# WBZ451 register map
Vendor: Microchip
Registers are 32-bit, read-write, reset 0x0 unless marked. A register's access mark holds for its fields unless they carry their own. Addresses are absolute, and some are shared; only a register's first bit layout is shown; [hi:lo] are bit positions; {n}, {i} and the like mark numbered series.

## DSCON
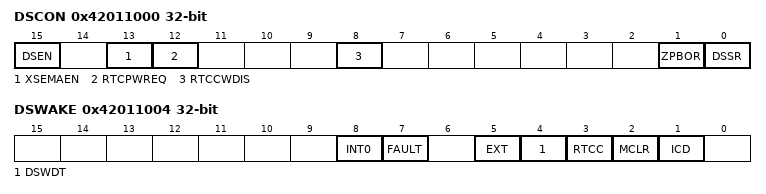
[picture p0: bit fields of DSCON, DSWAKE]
0x42011000 DSCON
  [15] DSEN, [13] XSEMAEN, [12] RTCPWREQ, [8] RTCCWDIS, [1] ZPBOR, [0] DSSR
0x42011004 DSWAKE
  [8] INT0, [7] FAULT, [5] EXT, [4] DSWDT, [3] RTCC, [2] MCLR, [1] ICD
0x42011008 DSSEMA1
  [31:0] DSSEMA
0x42011010 DSXSEMA1 reset not defined
  [31:0] DSXSEMA

## WDT
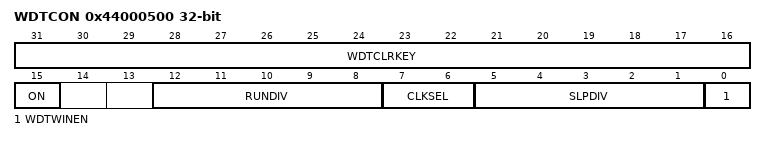
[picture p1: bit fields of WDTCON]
0x44000500 WDTCON reset not defined
  [31:16] WDTCLRKEY
  [15] ON — Watchdog Timer Enable bit
    1=WDTEN (The WDT module is enabled); 0=WDTOFF (The WDT module is disabled)
  [12:8] RUNDIV
  [7:6] CLKSEL
  [5:1] SLPDIV
  [0] WDTWINEN — Watchdog Timer Window Enable bit
    1=WDTWINEN (Enable windowed Watchdog Timer); 0=WDTWINDIS (Disable windowed Watchdog Timer)
0x44000504 WDTCONCLR
0x44000508 WDTCONSET
0x4400050C WDTCONINV

## NVM
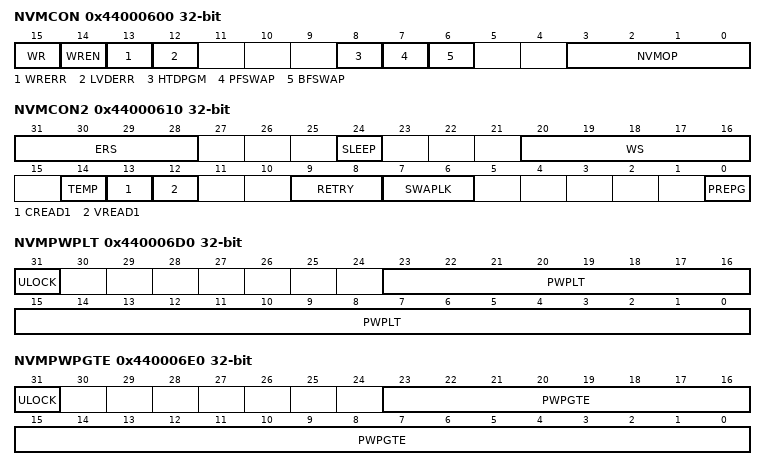
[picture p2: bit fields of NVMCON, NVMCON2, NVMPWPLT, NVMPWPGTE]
0x44000600 NVMCON
  [15] WR, [14] WREN, [13] WRERR, [12] LVDERR, [8] HTDPGM, [7] PFSWAP, [6] BFSWAP, [3:0] NVMOP
0x44000604 NVMCONCLR
0x44000608 NVMCONSET
0x4400060C NVMCONINV
0x44000610 NVMCON2
  [31:28] ERS, [24] SLEEP, [20:16] WS, [14] TEMP, [13] CREAD1, [12] VREAD1, [9:8] RETRY, [7:6] SWAPLK, [0] PREPG
0x44000614 NVMCON2CLR
0x44000618 NVMCON2SET
0x4400061C NVMCON2INV
0x44000620 NVMKEY
0x44000630 NVMADDR
{0x44000640+0x10*i} NVMDATA{i} (i=0..7)
0x440006C0 NVMSRCADDR
0x440006D0 NVMPWPLT
  [31] ULOCK, [23:0] PWPLT
0x440006D4 NVMPWPLTCLR
0x440006D8 NVMPWPLTSET
0x440006DC NVMPWPLTINV
0x440006E0 NVMPWPGTE
  [31] ULOCK, [23:0] PWPGTE
0x440006E4 NVMPWPGTECLR
0x440006E8 NVMPWPGTESET
0x440006EC NVMPWPGTEINV
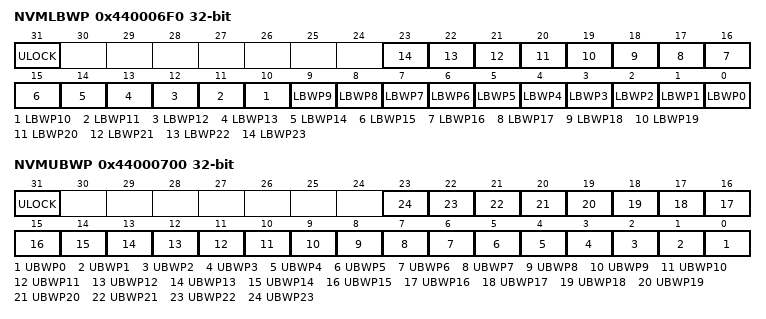
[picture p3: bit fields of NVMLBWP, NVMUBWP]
0x440006F0 NVMLBWP
  [31] ULOCK, [n] LBWP{n} (n=0..23)
0x440006F4 NVMLBWPCLR
0x440006F8 NVMLBWPSET
0x440006FC NVMLBWPINV
0x44000700 NVMUBWP
  [31] ULOCK, [n] UBWP{n} (n=0..23)
0x44000704 NVMUBWPCLR
0x44000708 NVMUBWPSET
0x4400070C NVMUBWPINV

## PFW
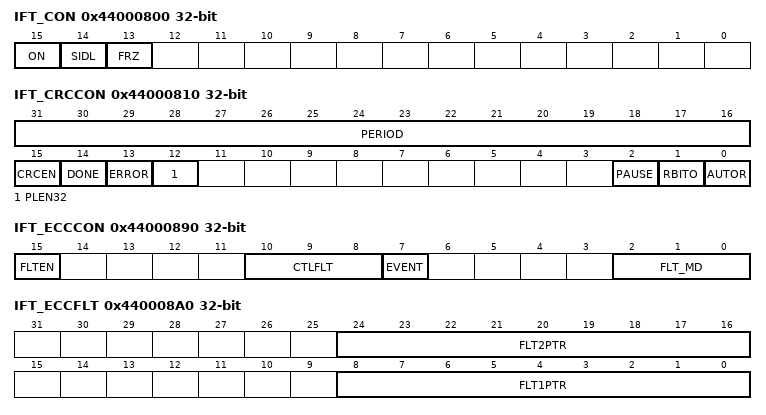
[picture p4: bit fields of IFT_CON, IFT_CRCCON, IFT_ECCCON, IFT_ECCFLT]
0x44000800 IFT_CON
  [15] ON, [14] SIDL, [13] FRZ
0x44000810 IFT_CRCCON
  [31:16] PERIOD, [15] CRCEN, [14] DONE, [13] ERROR, [12] PLEN32, [2] PAUSE, [1] RBITO, [0] AUTOR
0x44000820 IFT_CRCMADR
0x44000830 IFT_CRCMLEN
  [23:0] CRCMLEN
0x44000840 IFT_CRCIV
0x44000850 IFT_CRCACC
0x44000860 IFT_CRCPOLY
  [31:0] CYCPOLY
0x44000870 IFT_CRCFXOR
0x44000880 IFT_CRCSUM
0x44000890 IFT_ECCCON
  [15] FLTEN, [10:8] CTLFLT, [7] EVENT, [2:0] FLT_MD
0x440008A0 IFT_ECCFLT
  [24:16] FLT2PTR, [8:0] FLT1PTR
0x440008B0 IFT_ECCADR
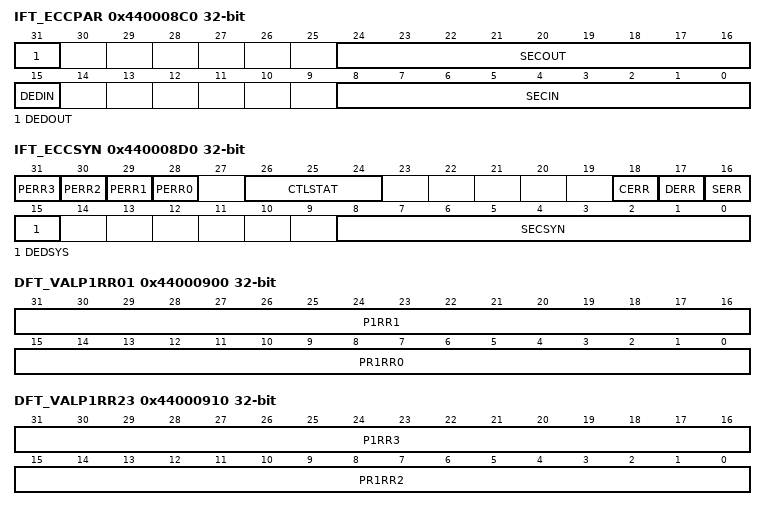
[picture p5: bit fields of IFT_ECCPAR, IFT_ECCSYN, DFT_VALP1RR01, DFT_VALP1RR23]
0x440008C0 IFT_ECCPAR
  [31] DEDOUT, [24:16] SECOUT, [15] DEDIN, [8:0] SECIN
0x440008D0 IFT_ECCSYN
  [n+28] PERR{n} (n=0..3), [26:24] CTLSTAT, [18] CERR, [17] DERR, [16] SERR, [15] DEDSYS, [8:0] SECSYN
0x440008F0 DFT_VALCON
  [15] VAL_ON
0x44000900 DFT_VALP1RR01
  [31:16] P1RR1, [15:0] PR1RR0
0x44000910 DFT_VALP1RR23
  [31:16] P1RR3, [15:0] PR1RR2
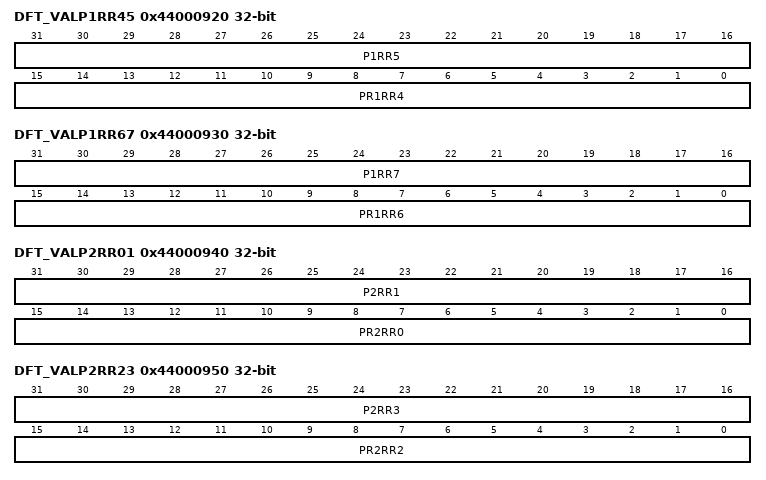
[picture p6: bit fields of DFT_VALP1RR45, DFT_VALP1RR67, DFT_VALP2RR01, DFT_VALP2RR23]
0x44000920 DFT_VALP1RR45
  [31:16] P1RR5, [15:0] PR1RR4
0x44000930 DFT_VALP1RR67
  [31:16] P1RR7, [15:0] PR1RR6
0x44000940 DFT_VALP2RR01
  [31:16] P2RR1, [15:0] PR2RR0
0x44000950 DFT_VALP2RR23
  [31:16] P2RR3, [15:0] PR2RR2
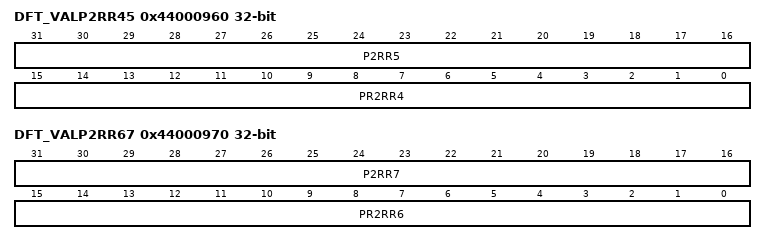
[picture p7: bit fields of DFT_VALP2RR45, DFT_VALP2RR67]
0x44000960 DFT_VALP2RR45
  [31:16] P2RR5, [15:0] PR2RR4
0x44000970 DFT_VALP2RR67
  [31:16] P2RR7, [15:0] PR2RR6

## DMT
0x44000E00 DMTCON
  [15] ON
0x44000E04 DMTCONCLR
0x44000E08 DMTCONSET
0x44000E0C DMTCONINV
0x44000E10 DMTPRECLR
  [15:8] STEP1
0x44000E14 DMTPRECLRCLR
0x44000E18 DMTPRECLRSET
0x44000E1C DMTPRECLRINV
0x44000E20 DMTCLR
  [7:0] STEP2
0x44000E24 DMTCLRCLR
0x44000E28 DMTCLRSET
0x44000E2C DMTCLRINV
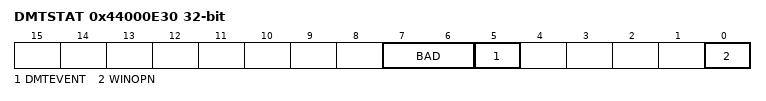
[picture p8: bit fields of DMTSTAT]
0x44000E30 DMTSTAT
  [7:6] BAD, [5] DMTEVENT, [0] WINOPN
0x44000E34 DMTSTATCLR
0x44000E38 DMTSTATSET
0x44000E3C DMTSTATINV
0x44000E40 DMTCNT
  [31:0] COUNTER
0x44000E44 DMTCNTCLR
0x44000E48 DMTCNTSET
0x44000E4C DMTCNTINV
0x44000E50 DMTHOLDREG
  [15:0] UPRCNT
0x44000E54 DMTHOLDREGCLR
0x44000E58 DMTHOLDREGSET
0x44000E5C DMTHOLDREGINV
0x44000E60 DMTPSCNT
  [31:0] PSCNT
0x44000E64 DMTPSCNTCLR
0x44000E68 DMTPSCNTSET
0x44000E6C DMTPSCNTINV
0x44000E70 DMTPSINTV
  [31:0] PSINTV
0x44000E74 DMTPSINTVCLR
0x44000E78 DMTPSINTVSET
0x44000E7C DMTPSINTVINV
